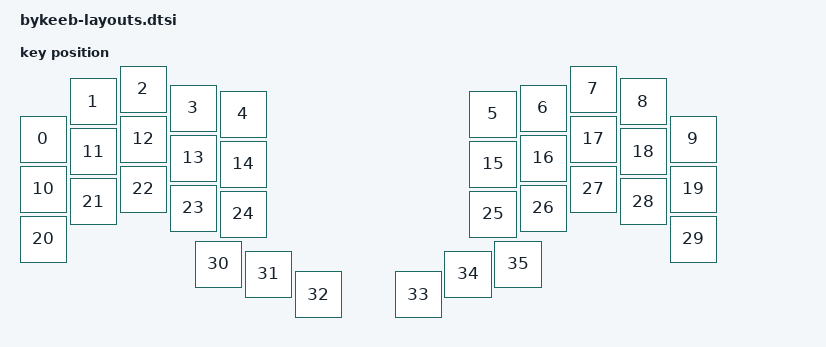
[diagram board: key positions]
/* SPDX-License-Identifier: MIT */
#include <physical_layouts.dtsi>

/ {
    bykeeb_layout: bykeeb_layout {
        compatible = "zmk,physical-layout";
        display-name = "Bykeeb 36";
        kscan = <&kscan0>;
        transform = <&default_transform>;
        // Display geometry follows the existing layout diagram; wiring is unchanged.
        keys =
            <&key_physical_attrs 100 100 0 100 (0) 50 150>,
            <&key_physical_attrs 100 100 100 25 (0) 150 75>,
            <&key_physical_attrs 100 100 200 0 (0) 250 50>,
            <&key_physical_attrs 100 100 300 38 (0) 350 88>,
            <&key_physical_attrs 100 100 400 50 (0) 450 100>,
            <&key_physical_attrs 100 100 900 50 (0) 950 100>,
            <&key_physical_attrs 100 100 1000 38 (0) 1050 88>,
            <&key_physical_attrs 100 100 1100 0 (0) 1150 50>,
            <&key_physical_attrs 100 100 1200 25 (0) 1250 75>,
            <&key_physical_attrs 100 100 1300 100 (0) 1350 150>,
            <&key_physical_attrs 100 100 0 200 (0) 50 250>,
            <&key_physical_attrs 100 100 100 125 (0) 150 175>,
            <&key_physical_attrs 100 100 200 100 (0) 250 150>,
            <&key_physical_attrs 100 100 300 138 (0) 350 188>,
            <&key_physical_attrs 100 100 400 150 (0) 450 200>,
            <&key_physical_attrs 100 100 900 150 (0) 950 200>,
            <&key_physical_attrs 100 100 1000 138 (0) 1050 188>,
            <&key_physical_attrs 100 100 1100 100 (0) 1150 150>,
            <&key_physical_attrs 100 100 1200 125 (0) 1250 175>,
            <&key_physical_attrs 100 100 1300 200 (0) 1350 250>,
            <&key_physical_attrs 100 100 0 300 (0) 50 350>,
            <&key_physical_attrs 100 100 100 225 (0) 150 275>,
            <&key_physical_attrs 100 100 200 200 (0) 250 250>,
            <&key_physical_attrs 100 100 300 238 (0) 350 288>,
            <&key_physical_attrs 100 100 400 250 (0) 450 300>,
            <&key_physical_attrs 100 100 900 250 (0) 950 300>,
            <&key_physical_attrs 100 100 1000 238 (0) 1050 288>,
            <&key_physical_attrs 100 100 1100 200 (0) 1150 250>,
            <&key_physical_attrs 100 100 1200 225 (0) 1250 275>,
            <&key_physical_attrs 100 100 1300 300 (0) 1350 350>,
            <&key_physical_attrs 100 100 350 350 (0) 400 400>,
            <&key_physical_attrs 100 100 450 370 (0) 500 420>,
            <&key_physical_attrs 100 100 550 411 (0) 600 461>,
            <&key_physical_attrs 100 100 750 411 (0) 800 461>,
            <&key_physical_attrs 100 100 850 370 (0) 900 420>,
            <&key_physical_attrs 100 100 950 350 (0) 1000 400>
            ;
    };
};
